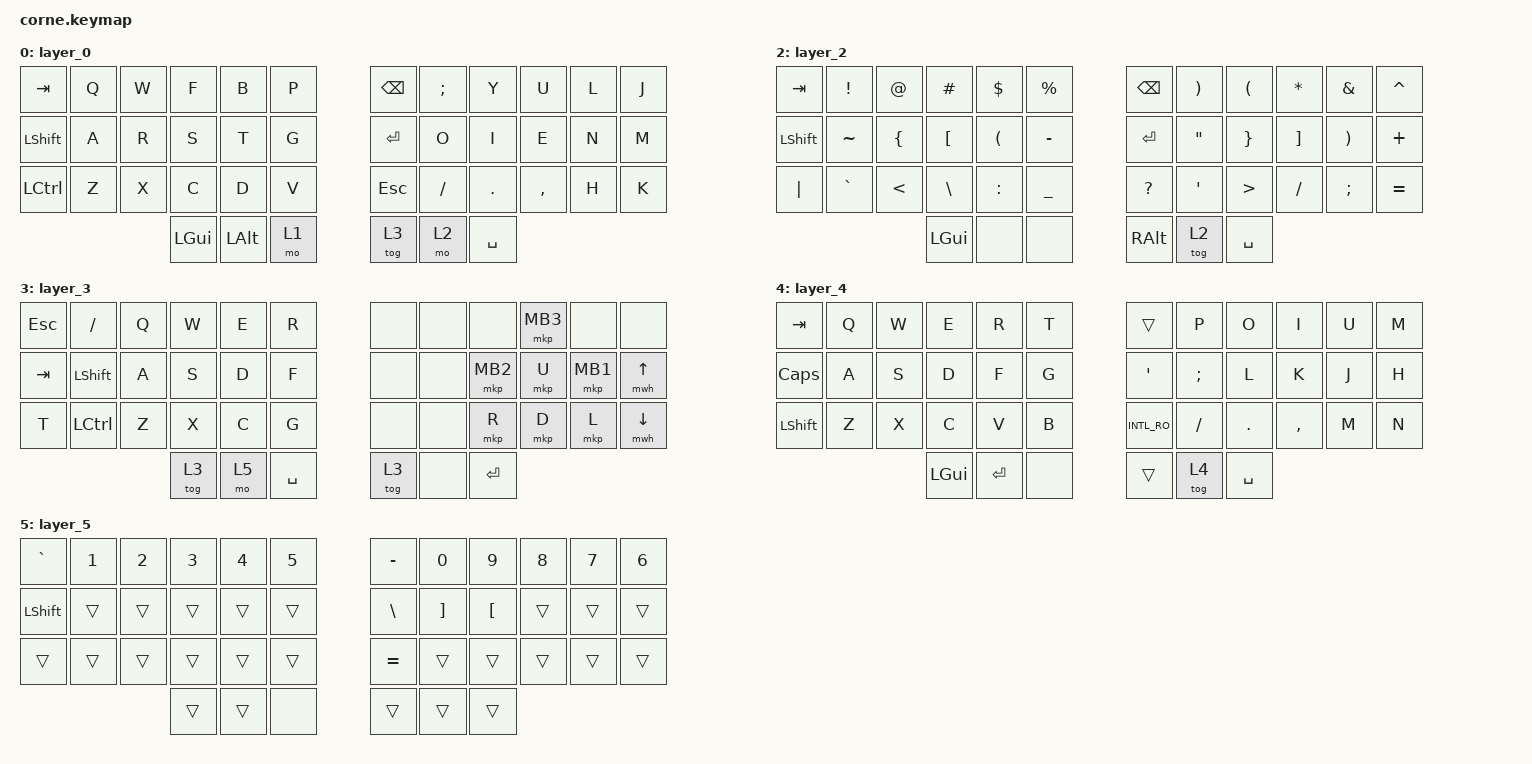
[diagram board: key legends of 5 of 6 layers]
/*
 * Copyright (c) 2020 The ZMK Contributors
 *
 * SPDX-License-Identifier: MIT
 */

#include <behaviors.dtsi>
#include <dt-bindings/zmk/keys.h>
#include <dt-bindings/zmk/bt.h>
#include <dt-bindings/zmk/mouse.h> // Include for mouse key codes

// Helper macro for QMK-like shifted keys (if not already defined elsewhere)

/ {
    keymap {
        compatible = "zmk,keymap";

        // Base Layer (Layer 0)
        layer_0 {
            bindings = <
                &kp TAB      &kp Q          &kp W          &kp F          &kp B          &kp P             &kp BSPC       &kp SEMI       &kp Y          &kp U          &kp L          &kp J
                &kp LSHFT    &kp A          &kp R          &kp S          &kp T          &kp G             &kp RET        &kp O          &kp I          &kp E          &kp N          &kp M
                &kp LCTRL    &kp Z          &kp X          &kp C          &kp D          &kp V             &kp ESC        &kp FSLH       &kp DOT        &kp COMMA      &kp H          &kp K
                                            &kp LGUI       &kp LALT       &mo 1                             &tog 3         &mo 2          &kp SPACE
            >;
        };

        // Layer 1 (Accessed by MO(1) from Layer 0)
        layer_1 {
            bindings = <
                &kp ESC      &kp N1         &kp N2         &kp N3         &kp N4         &kp N5            &kp BSPC       &kp N0         &kp N9         &kp N8         &kp N7         &kp N6
                &kp CAPS     &kp LCTRL A    &none          &none          &kp LCTRL N    &none             &kp RET        &kp DQT        &kp END        &kp UP         &kp HOME       &none
                &kp LCTRL    &none          &none          &kp LCTRL C    &none          &kp LCTRL V       &kp DEL        &none          &kp RIGHT      &kp DOWN       &kp LEFT       &none
                                            &kp LGUI       &trans         &trans                            &none          &none          &kp SPACE
            >;
        };

        // Layer 2 (Accessed by MO(2) from Layer 0 or TG(2) from Layer 2)
        layer_2 {
            bindings = <
                &kp TAB      &kp EXCL       &kp AT         &kp HASH       &kp DLLR       &kp PRCNT         &kp BSPC       &kp RPAR       &kp LPAR       &kp ASTRK      &kp AMPS       &kp CARET
                &kp LSHFT    &kp TILDE      &kp LBRC       &kp LBKT       &kp LPAR       &kp MINUS         &kp RET        &kp DQT        &kp RBRC       &kp RBKT       &kp RPAR       &kp PLUS
                &kp PIPE     &kp GRAVE      &kp LT         &kp BSLH       &kp COLON      &kp UNDER         &kp QMARK      &kp SQT        &kp GT         &kp FSLH       &kp SEMI       &kp EQUAL
                                            &kp LGUI       &none          &none                             &kp RALT       &tog 2         &kp SPACE
            >;
        };

        // Layer 3 (Accessed by TG(3) from Layer 0 or Layer 3) - Mouse Layer
        // NOTE: Requires CONFIG_ZMK_MOUSE=y in your .conf file
        layer_3 {
            bindings = <
                &kp ESC      &kp FSLH       &kp Q          &kp W          &kp E          &kp R             &none          &none          &none          &mkp MB3       &none          &none
                &kp TAB      &kp LSHFT      &kp A          &kp S          &kp D          &kp F             &none          &none          &mkp MB2       &mkp U         &mkp MB1       &mwh UP
                &kp T        &kp LCTRL      &kp Z          &kp X          &kp C          &kp G             &none          &none          &mkp R         &mkp D         &mkp L         &mwh DOWN
                                            &tog 3         &mo 5          &kp SPACE                         &tog 3         &none          &kp RET
            >;
            // Note: KC_ACL0 was mapped to &none as its ZMK equivalent is unclear.
        };

        // Layer 4 (Accessed by TG(4) from Layer 4)
        layer_4 {
            bindings = <
                &kp TAB      &kp Q          &kp W          &kp E          &kp R          &kp T             &trans         &kp P          &kp O          &kp I          &kp U          &kp M
                &kp CAPS     &kp A          &kp S          &kp D          &kp F          &kp G             &kp SQT        &kp SEMI       &kp L          &kp K          &kp J          &kp H
                &kp LSHFT    &kp Z          &kp X          &kp C          &kp V          &kp B             &kp INTL_RO    &kp FSLH       &kp DOT        &kp COMMA      &kp M          &kp N
                                            &kp LGUI       &kp RET        &none                             &trans         &tog 4         &kp SPACE
            >;
            // Note: M0 was mapped to &kp M, assuming it was a typo for KC_M.
        };

        // Layer 5 (Accessed by MO(5) from Layer 3)
        layer_5 {
            bindings = <
                &kp GRAVE    &kp N1         &kp N2         &kp N3         &kp N4         &kp N5            &kp MINUS      &kp N0         &kp N9         &kp N8         &kp N7         &kp N6
                &kp LSHFT    &trans         &trans         &trans         &trans         &trans            &kp BSLH       &kp RBKT       &kp LBKT       &trans         &trans         &trans
                &trans       &trans         &trans         &trans         &trans         &trans            &kp EQUAL      &trans         &trans         &trans         &trans         &trans
                                            &trans         &trans         &none                             &trans         &trans         &trans
            >;
        };

        // Layers 6-15 were empty (&trans) in the source file and are omitted here.
    };
};
